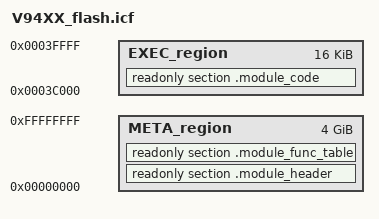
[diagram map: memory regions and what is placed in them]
/*==========================================================
  PHASE-1 MODULE LINKER SCRIPT (IAR)
==========================================================*/

define memory mem with size = 4G;

/* Execution window (must match loader) */
define region EXEC_region =
    mem:[from 0x0003C000 to 0x0003FFFF];

/* Region for metadata (external-flash image layout) */
define region META_region =
    mem:[from 0x00000000 to 0xFFFFFFFF];

/* Executable code (copied by loader to internal flash) */
place in EXEC_region
{
    readonly section .module_code
};

/* Metadata sections (stored in external flash only) */
place in META_region
{
    readonly section .module_header,
    readonly section .module_func_table
};

/* Forbidden sections (Phase-1 discipline) */

